# APM32F411 register map
Vendor: Geehy; File version: 2024.11.05
CPU: CM4 r1p0, little endian, 3 interrupt priority bits
Registers are 32-bit, read-write, reset 0x0 unless marked. A register's access mark holds for its fields unless they carry their own. Offsets are from the block's base; [hi:lo] are bit positions; {n}, {i} and the like mark numbered series.

## SDIO — Secure digital input/output interface
Base 0x40012C00
0x00 PWRCTRL — power control register
  [1:0] PWRCTRL — Power Supply Control
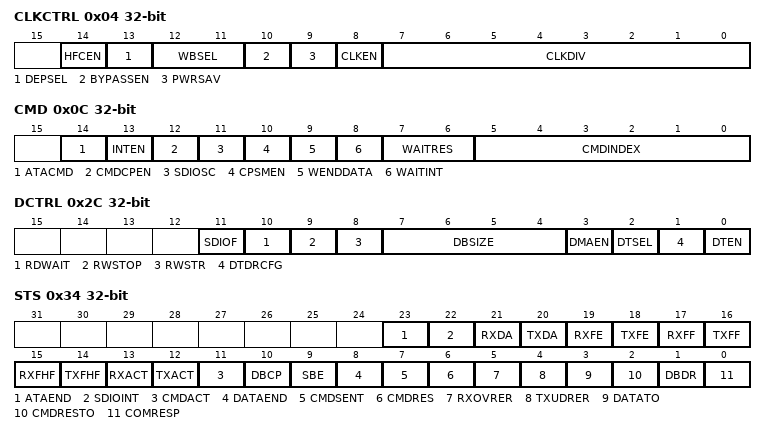
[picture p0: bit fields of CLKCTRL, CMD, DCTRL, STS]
0x04 CLKCTRL — SDI clock control register
  [14] HFCEN — HW Flow Control enable
  [13] DEPSEL — SDIO_CK dephasing selection bit
  [12:11] WBSEL — Wide bus mode enable bit
  [10] BYPASSEN — Clock divider bypass enable bit
  [9] PWRSAV — Power saving configuration bit
  [8] CLKEN — Clock enable bit
  [7:0] CLKDIV — Clock divide factor
0x08 ARG — argument register
  [31:0] CMDARG — Command argument
0x0C CMD — command register
  [14] ATACMD — CE-ATA command
  [13] INTEN — not Interrupt Enable
  [12] CMDCPEN — Enable CMD completion
  [11] SDIOSC — SD I/O suspend command
  [10] CPSMEN — Command path state machine (CPSM) Enable bit
  [9] WENDDATA — CPSM Waits for ends of data transfer (CmdPend internal signal).
  [8] WAITINT — CPSM waits for interrupt request
  [7:6] WAITRES — Wait for response bits
  [5:0] CMDINDEX — Command index
0x10 CMDRES ro — command response register
  [5:0] CMDRES — Response command index
{0x10+4i} RES{i} ro (i=1..4) — response {i} register
  [31:0] CARDSTS{i} — Card status
0x24 DATATIME — data timer register
  [31:0] DATATIME — Data timeout period
0x28 DATALEN — data length register
  [24:0] DATALEN — Data length value
0x2C DCTRL — data control register
  [11] SDIOF — SD I/O enable functions
  [10] RDWAIT — Read wait mode
  [9] RWSTOP — Read wait stop
  [8] RWSTR — Read wait start
  [7:4] DBSIZE — Data block size
  [3] DMAEN — DMA enable bit
  [2] DTSEL — Data transfer mode selection 1: Stream or SDIO multibyte data transfer.
  [1] DTDRCFG — Data transfer direction selection
  [0] DTEN — Data Transfer Enabled
0x30 DCNT ro — data counter register
  [24:0] DATACNT — Data count value
0x34 STS ro — status register
  [23] ATAEND — CE-ATA command completion signal received for CMD61
  [22] SDIOINT — SDIO interrupt received
  [21] RXDA — Data available in receive FIFO
  [20] TXDA — Data available in transmit FIFO
  [19] RXFE — Receive FIFO empty
  [18] TXFE — Transmit FIFO empty
  [17] RXFF — Receive FIFO full
  [16] TXFF — Transmit FIFO full
  [15] RXFHF — Receive FIFO half full: there are at least 8 words in the FIFO
  [14] TXFHF — Transmit FIFO half empty: at least 8 words can be written into the FIFO
  [13] RXACT — Data receive in progress
  [12] TXACT — Data transmit in progress
  [11] CMDACT — Command transfer in progress
  [10] DBCP — Data block sent/received (CRC check passed)
  [9] SBE — Start bit not detected on all data signals in wide bus mode
  [8] DATAEND — Data end (data counter, SDIDCOUNT, is zero)
  [7] CMDSENT — Command sent (no response required)
  [6] CMDRES — Command response received (CRC check passed)
  [5] RXOVRER — Received FIFO overrun error
  [4] TXUDRER — Transmit FIFO underrun error
  [3] DATATO — Data timeout
  [2] CMDRESTO — Command response timeout
  [1] DBDR — Data block sent/received (CRC check failed)
  [0] COMRESP — Command response received (CRC check failed)
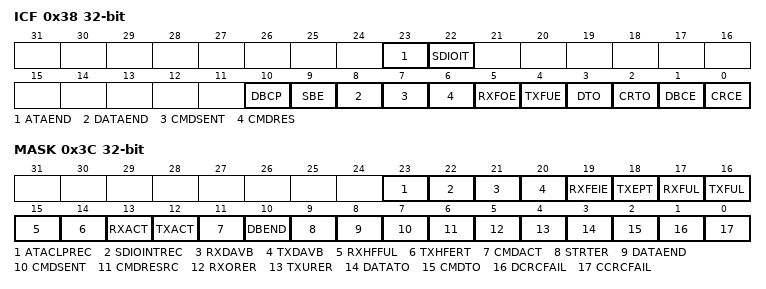
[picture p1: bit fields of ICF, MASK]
0x38 ICF — interrupt clear register
  [23] ATAEND — ATAEND flag clear bit
  [22] SDIOIT — SDIOIT flag clear bit
  [10] DBCP — DBCP flag clear bit
  [9] SBE — SBE flag clear bit
  [8] DATAEND — DATAEND flag clear bit
  [7] CMDSENT — CMDSENT flag clear bit
  [6] CMDRES — CMDRES flag clear bit
  [5] RXFOE — RXFOE flag clear bit
  [4] TXFUE — TXFUE flag clear bit
  [3] DTO — DTO flag clear bit
  [2] CRTO — CRTO flag clear bit
  [1] DBCE — DBDR flag clear bit
  [0] CRCE — COMRESP flag clear bit
0x3C MASK
  [23] ATACLPREC — CE-ATA command completion signal received interrupt enable
  [22] SDIOINTREC — SDIO mode interrupt received interrupt enable
  [21] RXDAVB — Data available in Rx FIFO interrupt enable
  [20] TXDAVB — Data available in Tx FIFO interrupt enable
  [19] RXFEIE — Rx FIFO empty interrupt enable
  [18] TXEPT — Tx FIFO empty interrupt enable
  [17] RXFUL — Rx FIFO full interrupt enable
  [16] TXFUL — Tx FIFO full interrupt enable
  [15] RXHFFUL — Rx FIFO half full interrupt enable
  [14] TXHFERT — Tx FIFO half empty interrupt enable
  [13] RXACT — Data receive acting interrupt enable
  [12] TXACT — Data transmit acting interrupt enable
  [11] CMDACT — Command acting interrupt enable
  [10] DBEND — Data block end interrupt enable
  [9] STRTER — Start bit error interrupt enable
  [8] DATAEND — Data end interrupt enable
  [7] CMDSENT — Command sent interrupt enable
  [6] CMDRESRC — Command response received interrupt enable
  [5] RXORER — Rx FIFO overrun error interrupt enable
  [4] TXURER — Tx FIFO underrun error interrupt enable
  [3] DATATO — Data timeout interrupt enable
  [2] CMDTO — Command timeout interrupt enable
  [1] DCRCFAIL — Data CRC fail interrupt enable
  [0] CCRCFAIL — Command CRC fail interrupt enable
0x48 FIFOCNT ro — FIFO counter register
  [23:0] FIFOCNT — Remaining number of words to be written to or read from the FIFO.
0x80 FIFODATA — data FIFO register
  [31:0] DATA — Receive and transmit FIFO data
